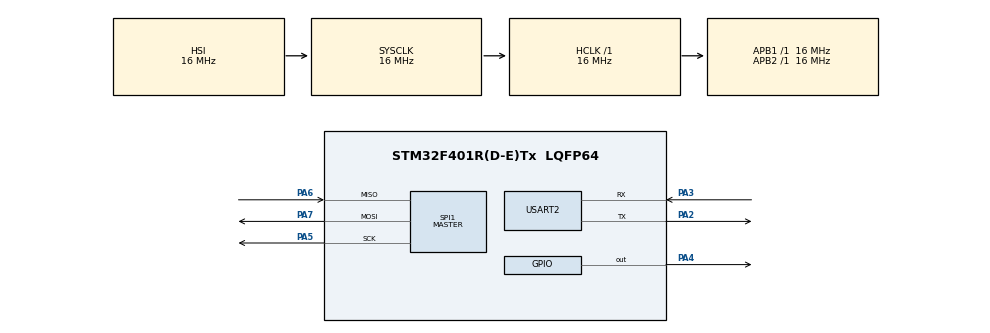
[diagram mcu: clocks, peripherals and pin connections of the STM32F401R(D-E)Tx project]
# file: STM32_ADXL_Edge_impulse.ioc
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Mcu.Family=STM32F4
Mcu.Name=STM32F401R(D-E)Tx
Mcu.Package=LQFP64
NVIC.PriorityGroup=NVIC_PRIORITYGROUP_4
PA2.Mode=Asynchronous
PA2.Signal=USART2_TX
PA3.Mode=Asynchronous
PA3.Signal=USART2_RX
PA4.Signal=GPIO_Output
PA5.Mode=Full_Duplex_Master
PA5.Signal=SPI1_SCK
PA6.Mode=Full_Duplex_Master
PA6.Signal=SPI1_MISO
PA7.Mode=Full_Duplex_Master
PA7.Signal=SPI1_MOSI
ProjectManager.HeapSize=0x200
ProjectManager.StackSize=0x400
ProjectManager.TargetToolchain=STM32CubeIDE
RCC.AHBFreq_Value=16000000
RCC.APB1Freq_Value=16000000
RCC.APB2Freq_Value=16000000
RCC.CortexFreq_Value=16000000
RCC.HSE_VALUE=25000000
RCC.HSI_VALUE=16000000
RCC.LSE_VALUE=32768
RCC.SYSCLKFreq_VALUE=16000000
RCC.VCOOutputFreq_Value=192000000
SPI1.BaudRatePrescaler=SPI_BAUDRATEPRESCALER_64
SPI1.CLKPhase=SPI_PHASE_2EDGE
SPI1.CLKPolarity=SPI_POLARITY_HIGH
SPI1.Direction=SPI_DIRECTION_2LINES
SPI1.Mode=SPI_MODE_MASTER
SPI1.VirtualType=VM_MASTER
USART2.VirtualMode=VM_ASYNC
board=custom

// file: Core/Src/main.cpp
/*
 * main.cpp
 *
 *  Created on: 23-Jun-2026
 *      Author: veena
 */

extern "C" {
#include "main.h"
}

#include <stdio.h>
#include <string.h>

#include "edge-impulse-sdk/classifier/ei_run_classifier.h"
#include "model-parameters/model_metadata.h"

float feature_buffer[EI_CLASSIFIER_DSP_INPUT_FRAME_SIZE];
int buf_index = 0;

#define TEST_SIZE EI_CLASSIFIER_DSP_INPUT_FRAME_SIZE

void SystemClock_Config(void);
static void MX_GPIO_Init(void);
static void MX_SPI1_Init(void);
static void MX_USART2_UART_Init(void);

SPI_HandleTypeDef hspi1;

UART_HandleTypeDef huart2;

int raw_feature_get_data(size_t offset,
                         size_t length,
                         float *out_ptr)
{
    memcpy(out_ptr,
           feature_buffer + offset,
           length * sizeof(float));

    return 0;
}

void ADXL345_SPI_Write(uint8_t reg, uint8_t data)
{
    uint8_t tx[2];

    tx[0] = reg & 0x3F;      // write operation
    tx[1] = data;

    HAL_GPIO_WritePin(GPIOA, GPIO_PIN_4, GPIO_PIN_RESET);   // CS low

    HAL_SPI_Transmit(&hspi1, tx, 2, HAL_MAX_DELAY);

    HAL_GPIO_WritePin(GPIOA, GPIO_PIN_4, GPIO_PIN_SET);     // CS high
}

uint8_t ADXL345_SPI_Read(uint8_t reg)
{
    uint8_t tx = reg | 0x80;      // read bit
    uint8_t rx;

    HAL_GPIO_WritePin(GPIOA, GPIO_PIN_4, GPIO_PIN_RESET);

    HAL_SPI_Transmit(&hspi1, &tx, 1, HAL_MAX_DELAY);
    HAL_SPI_Receive(&hspi1, &rx, 1, HAL_MAX_DELAY);

    HAL_GPIO_WritePin(GPIOA, GPIO_PIN_4, GPIO_PIN_SET);

    return rx;
}

void ADXL345_ReadXYZ(int16_t *x, int16_t *y, int16_t *z)
{
    uint8_t tx = 0x32 | 0xC0;     // multibyte + read
    uint8_t data[6];

    HAL_GPIO_WritePin(GPIOA, GPIO_PIN_4, GPIO_PIN_RESET);

    HAL_SPI_Transmit(&hspi1, &tx, 1, HAL_MAX_DELAY);
    HAL_SPI_Receive(&hspi1, data, 6, HAL_MAX_DELAY);

    HAL_GPIO_WritePin(GPIOA, GPIO_PIN_4, GPIO_PIN_SET);

    *x = (int16_t)((data[1] << 8) | data[0]);
    *y = (int16_t)((data[3] << 8) | data[2]);
    *z = (int16_t)((data[5] << 8) | data[4]);
}
//extern "C" int main(void)
int main(void)
{

  /* MCU Configuration--------------------------------------------------------*/

  /* Reset of all peripherals, Initializes the Flash interface and the Systick. */
  HAL_Init();

  /* Configure the system clock */
  SystemClock_Config();

  /* Initialize all configured peripherals */
  MX_GPIO_Init();
  MX_SPI1_Init();
  MX_USART2_UART_Init();
  /* USER CODE BEGIN 2 */

  HAL_GPIO_WritePin(GPIOA, GPIO_PIN_4, GPIO_PIN_SET);

  HAL_Delay(10);

  // Power control register
  ADXL345_SPI_Write(0x2D, 0x08);

  // Data format register ±2g
  ADXL345_SPI_Write(0x31, 0x00);

  // BW_RATE register 100Hz
  ADXL345_SPI_Write(0x2C, 0x0A);
  /* USER CODE END 2 */

  /* Infinite loop */
  /* USER CODE BEGIN WHILE */
  int16_t x, y, z;
  char msg[100];

  while (1)
  {
      // Read accelerometer values
      ADXL345_ReadXYZ(&x, &y, &z);

//      // Print as CSV format (recommended for Edge Impulse data forwarder)
//      sprintf(msg, "%d,%d,%d\r\n", x, y, z);
//
//      // Send over UART
//      HAL_UART_Transmit(&huart2,
//                        (uint8_t*)msg,
//                        strlen(msg),
//                        HAL_MAX_DELAY);
//
//      // Sampling interval = 20 ms (50 Hz)
//      HAL_Delay(20);
//  }

      feature_buffer[buf_index++] = (float)x;
      feature_buffer[buf_index++] = (float)y;
      feature_buffer[buf_index++] = (float)z;

      if (buf_index >= EI_CLASSIFIER_DSP_INPUT_FRAME_SIZE)
      {
          signal_t signal;

          signal.total_length =
              EI_CLASSIFIER_DSP_INPUT_FRAME_SIZE;

          signal.get_data = &raw_feature_get_data;

          ei_impulse_result_t result = {0};

          EI_IMPULSE_ERROR res =
              run_classifier(&signal,
                             &result,
                             false);

          if (res == EI_IMPULSE_OK)
          {
             ei_printf("\r\nPrediction:\r\n");

              for (size_t ix = 0;
                   ix < EI_CLASSIFIER_LABEL_COUNT;
                   ix++)
              {
                 ei_printf("%s : %.5f\r\n",
                         result.classification[ix].label,
                         result.classification[ix].value);
              }

             ei_printf("-----------------\r\n");
          }

          buf_index = 0;
      }

      HAL_Delay(20);
  }

}

void SystemClock_Config(void)
{
  RCC_OscInitTypeDef RCC_OscInitStruct = {0};
  RCC_ClkInitTypeDef RCC_ClkInitStruct = {0};

  /** Configure the main internal regulator output voltage
  */
  __HAL_RCC_PWR_CLK_ENABLE();
  __HAL_PWR_VOLTAGESCALING_CONFIG(PWR_REGULATOR_VOLTAGE_SCALE2);

  /** Initializes the RCC Oscillators according to the specified parameters
  * in the RCC_OscInitTypeDef structure.
  */
  RCC_OscInitStruct.OscillatorType = RCC_OSCILLATORTYPE_HSI;
  RCC_OscInitStruct.HSIState = RCC_HSI_ON;
  RCC_OscInitStruct.HSICalibrationValue = RCC_HSICALIBRATION_DEFAULT;
  RCC_OscInitStruct.PLL.PLLState = RCC_PLL_NONE;
  if (HAL_RCC_OscConfig(&RCC_OscInitStruct) != HAL_OK)
  {
    Error_Handler();
  }

  /** Initializes the CPU, AHB and APB buses clocks
  */
  RCC_ClkInitStruct.ClockType = RCC_CLOCKTYPE_HCLK|RCC_CLOCKTYPE_SYSCLK
                              |RCC_CLOCKTYPE_PCLK1|RCC_CLOCKTYPE_PCLK2;
  RCC_ClkInitStruct.SYSCLKSource = RCC_SYSCLKSOURCE_HSI;
  RCC_ClkInitStruct.AHBCLKDivider = RCC_SYSCLK_DIV1;
  RCC_ClkInitStruct.APB1CLKDivider = RCC_HCLK_DIV1;
  RCC_ClkInitStruct.APB2CLKDivider = RCC_HCLK_DIV1;

  if (HAL_RCC_ClockConfig(&RCC_ClkInitStruct, FLASH_LATENCY_0) != HAL_OK)
  {
    Error_Handler();
  }
}

static void MX_SPI1_Init(void)
{

  /* SPI1 parameter configuration*/
  hspi1.Instance = SPI1;
  hspi1.Init.Mode = SPI_MODE_MASTER;
  hspi1.Init.Direction = SPI_DIRECTION_2LINES;
  hspi1.Init.DataSize = SPI_DATASIZE_8BIT;
  hspi1.Init.CLKPolarity = SPI_POLARITY_HIGH;
  hspi1.Init.CLKPhase = SPI_PHASE_2EDGE;
  hspi1.Init.NSS = SPI_NSS_SOFT;
  hspi1.Init.BaudRatePrescaler = SPI_BAUDRATEPRESCALER_64;
  hspi1.Init.FirstBit = SPI_FIRSTBIT_MSB;
  hspi1.Init.TIMode = SPI_TIMODE_DISABLE;
  hspi1.Init.CRCCalculation = SPI_CRCCALCULATION_DISABLE;
  hspi1.Init.CRCPolynomial = 10;
  if (HAL_SPI_Init(&hspi1) != HAL_OK)
  {
    Error_Handler();
  }

}

static void MX_USART2_UART_Init(void)
{

  huart2.Instance = USART2;
  huart2.Init.BaudRate = 115200;
  huart2.Init.WordLength = UART_WORDLENGTH_8B;
  huart2.Init.StopBits = UART_STOPBITS_1;
  huart2.Init.Parity = UART_PARITY_NONE;
  huart2.Init.Mode = UART_MODE_TX_RX;
  huart2.Init.HwFlowCtl = UART_HWCONTROL_NONE;
  huart2.Init.OverSampling = UART_OVERSAMPLING_16;
  if (HAL_UART_Init(&huart2) != HAL_OK)
  {
    Error_Handler();
  }

}

static void MX_GPIO_Init(void)
{
  GPIO_InitTypeDef GPIO_InitStruct = {0};

  /* GPIO Ports Clock Enable */
  __HAL_RCC_GPIOA_CLK_ENABLE();

  /*Configure GPIO pin Output Level */
  HAL_GPIO_WritePin(GPIOA, GPIO_PIN_4, GPIO_PIN_RESET);

  /*Configure GPIO pin : PA4 */
  GPIO_InitStruct.Pin = GPIO_PIN_4;
  GPIO_InitStruct.Mode = GPIO_MODE_OUTPUT_PP;
  GPIO_InitStruct.Pull = GPIO_NOPULL;
  GPIO_InitStruct.Speed = GPIO_SPEED_FREQ_LOW;
  HAL_GPIO_Init(GPIOA, &GPIO_InitStruct);

}

void Error_Handler(void)
{
  __disable_irq();
  while (1)
  {
  }
}
